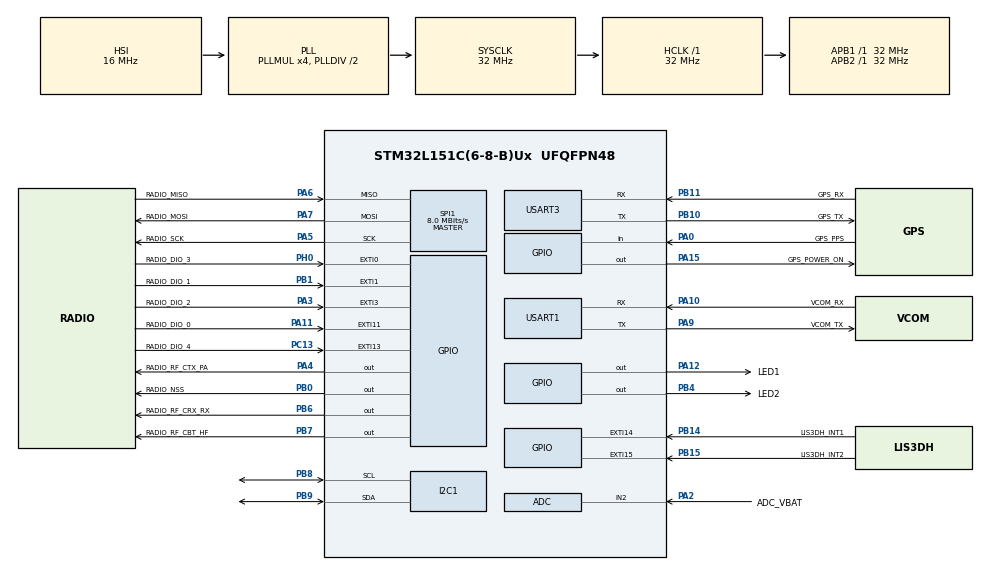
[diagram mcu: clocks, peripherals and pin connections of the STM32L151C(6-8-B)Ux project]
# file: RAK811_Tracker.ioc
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ADC.Channel-0\#ChannelRegularConversion=ADC_CHANNEL_2
ADC.ClockPrescaler=ADC_CLOCK_ASYNC_DIV1
ADC.ContinuousConvMode=DISABLE
ADC.DMAContinuousRequests=DISABLE
ADC.DataAlign=ADC_DATAALIGN_RIGHT
ADC.DiscontinuousConvMode=DISABLE
ADC.EOCSelection=ADC_EOC_SEQ_CONV
ADC.EnableAnalogWatchDog=false
ADC.ExternalTrigConv=ADC_SOFTWARE_START
ADC.ExternalTrigConvEdge=ADC_EXTERNALTRIGCONVEDGE_NONE
ADC.InjNumberOfConversion=0
ADC.LowPowerAutoPowerOff=ADC_AUTOPOWEROFF_DISABLE
ADC.LowPowerAutoWait=ADC_AUTOWAIT_DISABLE
ADC.NbrOfConversion=1
ADC.NbrOfConversionFlag=1
ADC.Rank-0\#ChannelRegularConversion=1
ADC.Resolution=ADC_RESOLUTION_12B
ADC.SamplingTime-0\#ChannelRegularConversion=ADC_SAMPLETIME_4CYCLES
ADC.ScanConvMode=ADC_SCAN_DISABLE
Dma.Request0=USART1_TX
Dma.USART1_TX.0.Direction=DMA_MEMORY_TO_PERIPH
Dma.USART1_TX.0.Instance=DMA1_Channel4
Dma.USART1_TX.0.MemDataAlignment=DMA_MDATAALIGN_BYTE
Dma.USART1_TX.0.MemInc=DMA_MINC_ENABLE
Dma.USART1_TX.0.Mode=DMA_NORMAL
Dma.USART1_TX.0.PeriphDataAlignment=DMA_PDATAALIGN_BYTE
Dma.USART1_TX.0.PeriphInc=DMA_PINC_DISABLE
Dma.USART1_TX.0.Priority=DMA_PRIORITY_MEDIUM
FREERTOS.Tasks01=defaultTask,0,128,StartDefaultTask,Default,NULL
I2C1.I2C_Mode=I2C_Fast
Mcu.Family=STM32L1
Mcu.Name=STM32L151C(6-8-B)Ux
Mcu.Package=UFQFPN48
NVIC.ADC1_IRQn=true\:5\:0\:false\:false\:true\:true\:true
NVIC.DMA1_Channel4_IRQn=true\:5\:0\:false\:false\:true\:true\:false
NVIC.EXTI0_IRQn=true\:5\:0\:false\:false\:true\:true\:true
NVIC.EXTI15_10_IRQn=true\:5\:0\:false\:false\:true\:true\:true
NVIC.EXTI1_IRQn=true\:5\:0\:false\:false\:true\:true\:true
NVIC.EXTI3_IRQn=true\:5\:0\:false\:false\:true\:true\:true
NVIC.I2C1_EV_IRQn=true\:5\:0\:false\:false\:true\:true\:true
NVIC.PriorityGroup=NVIC_PRIORITYGROUP_4
NVIC.USART1_IRQn=true\:5\:0\:false\:false\:true\:true\:true
NVIC.USART3_IRQn=true\:5\:0\:false\:false\:true\:true\:true
PA0-WKUP1.GPIO_Label=GPS_PPS
PA0-WKUP1.Signal=GPIO_Input
PA10.GPIO_Label=VCOM_RX
PA10.Mode=Asynchronous
PA10.Signal=USART1_RX
PA11.GPIO_Label=RADIO_DIO_0
PA11.Signal=GPXTI11
PA12.GPIO_Label=LED1
PA12.Signal=GPIO_Output
PA13.Mode=Serial_Wire
PA13.Signal=SYS_JTMS-SWDIO
PA14.Mode=Serial_Wire
PA14.Signal=SYS_JTCK-SWCLK
PA15.GPIO_Label=GPS_POWER_ON
PA15.Signal=GPIO_Output
PA2.GPIO_Label=ADC_VBAT
PA2.Mode=IN2
PA2.Signal=ADC_IN2
PA3.GPIO_Label=RADIO_DIO_2
PA3.Signal=GPXTI3
PA4.GPIO_Label=RADIO_RF_CTX_PA
PA4.Signal=GPIO_Output
PA5.GPIO_Label=RADIO_SCK
PA5.Mode=Full_Duplex_Master
PA5.Signal=SPI1_SCK
PA6.GPIO_Label=RADIO_MISO
PA6.Mode=Full_Duplex_Master
PA6.Signal=SPI1_MISO
PA7.GPIO_Label=RADIO_MOSI
PA7.Mode=Full_Duplex_Master
PA7.Signal=SPI1_MOSI
PA9.GPIO_Label=VCOM_TX
PA9.Mode=Asynchronous
PA9.Signal=USART1_TX
PB0.GPIO_Label=RADIO_NSS
PB0.GPIO_PuPd=GPIO_PULLUP
PB0.PinState=GPIO_PIN_SET
PB0.Signal=GPIO_Output
PB1.GPIO_Label=RADIO_DIO_1
PB1.Signal=GPXTI1
PB10.GPIO_Label=GPS_TX
PB10.Mode=Asynchronous
PB10.Signal=USART3_TX
PB11.GPIO_Label=GPS_RX
PB11.Mode=Asynchronous
PB11.Signal=USART3_RX
PB14.GPIO_Label=LIS3DH_INT1
PB14.Signal=GPXTI14
PB15.GPIO_Label=LIS3DH_INT2
PB15.Signal=GPXTI15
PB4.GPIO_Label=LED2
PB4.Signal=GPIO_Output
PB6.GPIO_Label=RADIO_RF_CRX_RX
PB6.Signal=GPIO_Output
PB7.GPIO_Label=RADIO_RF_CBT_HF
PB7.Signal=GPIO_Output
PB8.Mode=I2C
PB8.Signal=I2C1_SCL
PB9.Mode=I2C
PB9.Signal=I2C1_SDA
PC13-WKUP2.GPIO_Label=RADIO_DIO_4
PC13-WKUP2.Signal=GPXTI13
PC14-OSC32_IN.Mode=LSE-External-Oscillator
PC14-OSC32_IN.Signal=RCC_OSC32_IN
PC15-OSC32_OUT.Mode=LSE-External-Oscillator
PC15-OSC32_OUT.Signal=RCC_OSC32_OUT
PH0-OSC_IN.GPIO_Label=RADIO_DIO_3
PH0-OSC_IN.Signal=GPXTI0
PH1-OSC_OUT.Signal=RCC_OSC_OUT
ProjectManager.HeapSize=0x200
ProjectManager.StackSize=0x400
ProjectManager.TargetToolchain=TrueSTUDIO
RCC.48MHZClocksFreq_Value=32000000
RCC.AHBFreq_Value=32000000
RCC.APB1Freq_Value=32000000
RCC.APB1TimFreq_Value=32000000
RCC.APB2Freq_Value=32000000
RCC.APB2TimFreq_Value=32000000
RCC.HCLKFreq_Value=32000000
RCC.HSE_VALUE=24000000
RCC.HSI_VALUE=16000000
RCC.MSI_VALUE=2097000
RCC.PLLMUL=RCC_PLL_MUL4
RCC.SYSCLKFreq_VALUE=32000000
RCC.SYSCLKSource=RCC_SYSCLKSOURCE_PLLCLK
RCC.VCOOutputFreq_Value=64000000
SPI1.BaudRatePrescaler=SPI_BAUDRATEPRESCALER_4
SPI1.CalculateBaudRate=8.0 MBits/s
SPI1.Direction=SPI_DIRECTION_2LINES
SPI1.Mode=SPI_MODE_MASTER
SPI1.VirtualType=VM_MASTER
USART1.VirtualMode=VM_ASYNC
USART3.VirtualMode=VM_ASYNC
VP_ADC_TempSens_Input.Mode=IN-TempSens
VP_CRC_VS_CRC.Mode=CRC_Activate
VP_FREERTOS_VS_ENABLE.Mode=Enabled
VP_IWDG_VS_IWDG.Mode=IWDG_Activate
VP_RTC_VS_RTC_Activate.Mode=RTC_Enabled
VP_RTC_VS_RTC_Calendar.Mode=RTC_Calendar
VP_TIM2_VS_ClockSourceINT.Mode=Internal
board=RAK811_Tracker

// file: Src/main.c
/**
  ******************************************************************************
  * @file           : main.c
  * @brief          : Main program body
  ******************************************************************************
  * This notice applies to any and all portions of this file
  * that are not between comment pairs USER CODE BEGIN and
  * USER CODE END. Other portions of this file, whether
  * inserted by the user or by software development tools
  * are owned by their respective copyright owners.
  *
  * Copyright (c) 2018 STMicroelectronics International N.V.
  * All rights reserved.
  *
  * Redistribution and use in source and binary forms, with or without
  * modification, are permitted, provided that the following conditions are met:
  *
  * 1. Redistribution of source code must retain the above copyright notice,
  *    this list of conditions and the following disclaimer.
  * 2. Redistributions in binary form must reproduce the above copyright notice,
  *    this list of conditions and the following disclaimer in the documentation
  *    and/or other materials provided with the distribution.
  * 3. Neither the name of STMicroelectronics nor the names of other
  *    contributors to this software may be used to endorse or promote products
  *    derived from this software without specific written permission.
  * 4. This software, including modifications and/or derivative works of this
  *    software, must execute solely and exclusively on microcontroller or
  *    microprocessor devices manufactured by or for STMicroelectronics.
  * 5. Redistribution and use of this software other than as permitted under
  *    this license is void and will automatically terminate your rights under
  *    this license.
  *
  * THIS SOFTWARE IS PROVIDED BY STMICROELECTRONICS AND CONTRIBUTORS "AS IS"
  * AND ANY EXPRESS, IMPLIED OR STATUTORY WARRANTIES, INCLUDING, BUT NOT
  * LIMITED TO, THE IMPLIED WARRANTIES OF MERCHANTABILITY, FITNESS FOR A
  * PARTICULAR PURPOSE AND NON-INFRINGEMENT OF THIRD PARTY INTELLECTUAL PROPERTY
  * RIGHTS ARE DISCLAIMED TO THE FULLEST EXTENT PERMITTED BY LAW. IN NO EVENT
  * SHALL STMICROELECTRONICS OR CONTRIBUTORS BE LIABLE FOR ANY DIRECT, INDIRECT,
  * INCIDENTAL, SPECIAL, EXEMPLARY, OR CONSEQUENTIAL DAMAGES (INCLUDING, BUT NOT
  * LIMITED TO, PROCUREMENT OF SUBSTITUTE GOODS OR SERVICES; LOSS OF USE, DATA,
  * OR PROFITS; OR BUSINESS INTERRUPTION) HOWEVER CAUSED AND ON ANY THEORY OF
  * LIABILITY, WHETHER IN CONTRACT, STRICT LIABILITY, OR TORT (INCLUDING
  * NEGLIGENCE OR OTHERWISE) ARISING IN ANY WAY OUT OF THE USE OF THIS SOFTWARE,
  * EVEN IF ADVISED OF THE POSSIBILITY OF SUCH DAMAGE.
  *
  ******************************************************************************
  */
#include "main.h"
#include "stm32l1xx_hal.h"
#include "cmsis_os.h"

/* USER CODE BEGIN Includes */
#include "hw.h"
#include "low_power_manager.h"
#include "lora.h"
#include "bsp.h"
#include "timeServer.h"
#include "vcom.h"
#include "version.h"
/* USER CODE END Includes */

ADC_HandleTypeDef hadc;

CRC_HandleTypeDef hcrc;

I2C_HandleTypeDef hi2c1;

IWDG_HandleTypeDef hiwdg;

RTC_HandleTypeDef hrtc;

SPI_HandleTypeDef hspi1;

TIM_HandleTypeDef htim2;

UART_HandleTypeDef huart1;
UART_HandleTypeDef huart3;
DMA_HandleTypeDef hdma_usart1_tx;

osThreadId defaultTaskHandle;

/* USER CODE BEGIN PV */
/* Private variables ---------------------------------------------------------*/

/* USER CODE END PV */

void SystemClock_Config(void);
static void MX_GPIO_Init(void);
static void MX_DMA_Init(void);
static void MX_USART1_UART_Init(void);
static void MX_USART3_UART_Init(void);
static void MX_I2C1_Init(void);
static void MX_ADC_Init(void);
static void MX_RTC_Init(void);
static void MX_CRC_Init(void);
static void MX_IWDG_Init(void);
static void MX_SPI1_Init(void);
static void MX_TIM2_Init(void);
void StartDefaultTask(void const * argument);

/* USER CODE BEGIN PFP */
/* Private function prototypes -----------------------------------------------*/

/* USER CODE END PFP */

int main(void)
{

  /* MCU Configuration----------------------------------------------------------*/

  /* Reset of all peripherals, Initializes the Flash interface and the Systick. */
  HAL_Init();

  /* Configure the system clock */
  SystemClock_Config();

  /* Initialize all configured peripherals */
  MX_GPIO_Init();
  MX_DMA_Init();
  MX_USART1_UART_Init();
  MX_USART3_UART_Init();
  MX_I2C1_Init();
  MX_ADC_Init();
  MX_RTC_Init();
  MX_CRC_Init();
  MX_IWDG_Init();
  MX_SPI1_Init();
  MX_TIM2_Init();

  /* Create the thread(s) */
  /* definition and creation of defaultTask */
  osThreadDef(defaultTask, StartDefaultTask, osPriorityNormal, 0, 128);
  defaultTaskHandle = osThreadCreate(osThread(defaultTask), NULL);

  /* Start scheduler */
  osKernelStart();

  /* We should never get here as control is now taken by the scheduler */

  /* Infinite loop */
  while (1)
  {

  }

}

void SystemClock_Config(void)
{

  RCC_OscInitTypeDef RCC_OscInitStruct;
  RCC_ClkInitTypeDef RCC_ClkInitStruct;
  RCC_PeriphCLKInitTypeDef PeriphClkInit;

    /**Configure the main internal regulator output voltage
    */
  __HAL_PWR_VOLTAGESCALING_CONFIG(PWR_REGULATOR_VOLTAGE_SCALE1);

    /**Initializes the CPU, AHB and APB busses clocks
    */
  RCC_OscInitStruct.OscillatorType = RCC_OSCILLATORTYPE_HSI|RCC_OSCILLATORTYPE_LSI;
  RCC_OscInitStruct.HSIState = RCC_HSI_ON;
  RCC_OscInitStruct.HSICalibrationValue = 16;
  RCC_OscInitStruct.LSIState = RCC_LSI_ON;
  RCC_OscInitStruct.PLL.PLLState = RCC_PLL_ON;
  RCC_OscInitStruct.PLL.PLLSource = RCC_PLLSOURCE_HSI;
  RCC_OscInitStruct.PLL.PLLMUL = RCC_PLL_MUL4;
  RCC_OscInitStruct.PLL.PLLDIV = RCC_PLL_DIV2;
  if (HAL_RCC_OscConfig(&RCC_OscInitStruct) != HAL_OK)
  {
    _Error_Handler(__FILE__, __LINE__);
  }

    /**Initializes the CPU, AHB and APB busses clocks
    */
  RCC_ClkInitStruct.ClockType = RCC_CLOCKTYPE_HCLK|RCC_CLOCKTYPE_SYSCLK
                              |RCC_CLOCKTYPE_PCLK1|RCC_CLOCKTYPE_PCLK2;
  RCC_ClkInitStruct.SYSCLKSource = RCC_SYSCLKSOURCE_PLLCLK;
  RCC_ClkInitStruct.AHBCLKDivider = RCC_SYSCLK_DIV1;
  RCC_ClkInitStruct.APB1CLKDivider = RCC_HCLK_DIV1;
  RCC_ClkInitStruct.APB2CLKDivider = RCC_HCLK_DIV1;

  if (HAL_RCC_ClockConfig(&RCC_ClkInitStruct, FLASH_LATENCY_1) != HAL_OK)
  {
    _Error_Handler(__FILE__, __LINE__);
  }

  PeriphClkInit.PeriphClockSelection = RCC_PERIPHCLK_RTC;
  PeriphClkInit.RTCClockSelection = RCC_RTCCLKSOURCE_LSI;
  if (HAL_RCCEx_PeriphCLKConfig(&PeriphClkInit) != HAL_OK)
  {
    _Error_Handler(__FILE__, __LINE__);
  }

    /**Configure the Systick interrupt time
    */
  HAL_SYSTICK_Config(HAL_RCC_GetHCLKFreq()/1000);

    /**Configure the Systick
    */
  HAL_SYSTICK_CLKSourceConfig(SYSTICK_CLKSOURCE_HCLK);

  /* SysTick_IRQn interrupt configuration */
  HAL_NVIC_SetPriority(SysTick_IRQn, 15, 0);
}

/* ADC init function */
static void MX_ADC_Init(void)
{

  ADC_ChannelConfTypeDef sConfig;

    /**Configure the global features of the ADC (Clock, Resolution, Data Alignment and number of conversion)
    */
  hadc.Instance = ADC1;
  hadc.Init.ClockPrescaler = ADC_CLOCK_ASYNC_DIV1;
  hadc.Init.Resolution = ADC_RESOLUTION_12B;
  hadc.Init.DataAlign = ADC_DATAALIGN_RIGHT;
  hadc.Init.ScanConvMode = ADC_SCAN_DISABLE;
  hadc.Init.EOCSelection = ADC_EOC_SEQ_CONV;
  hadc.Init.LowPowerAutoWait = ADC_AUTOWAIT_DISABLE;
  hadc.Init.LowPowerAutoPowerOff = ADC_AUTOPOWEROFF_DISABLE;
  hadc.Init.ChannelsBank = ADC_CHANNELS_BANK_A;
  hadc.Init.ContinuousConvMode = DISABLE;
  hadc.Init.NbrOfConversion = 1;
  hadc.Init.DiscontinuousConvMode = DISABLE;
  hadc.Init.ExternalTrigConv = ADC_SOFTWARE_START;
  hadc.Init.ExternalTrigConvEdge = ADC_EXTERNALTRIGCONVEDGE_NONE;
  hadc.Init.DMAContinuousRequests = DISABLE;
  if (HAL_ADC_Init(&hadc) != HAL_OK)
  {
    _Error_Handler(__FILE__, __LINE__);
  }

    /**Configure for the selected ADC regular channel its corresponding rank in the sequencer and its sample time.
    */
  sConfig.Channel = ADC_CHANNEL_2;
  sConfig.Rank = ADC_REGULAR_RANK_1;
  sConfig.SamplingTime = ADC_SAMPLETIME_4CYCLES;
  if (HAL_ADC_ConfigChannel(&hadc, &sConfig) != HAL_OK)
  {
    _Error_Handler(__FILE__, __LINE__);
  }

}

/* CRC init function */
static void MX_CRC_Init(void)
{

  hcrc.Instance = CRC;
  if (HAL_CRC_Init(&hcrc) != HAL_OK)
  {
    _Error_Handler(__FILE__, __LINE__);
  }

}

/* I2C1 init function */
static void MX_I2C1_Init(void)
{

  hi2c1.Instance = I2C1;
  hi2c1.Init.ClockSpeed = 400000;
  hi2c1.Init.DutyCycle = I2C_DUTYCYCLE_2;
  hi2c1.Init.OwnAddress1 = 0;
  hi2c1.Init.AddressingMode = I2C_ADDRESSINGMODE_7BIT;
  hi2c1.Init.DualAddressMode = I2C_DUALADDRESS_DISABLE;
  hi2c1.Init.OwnAddress2 = 0;
  hi2c1.Init.GeneralCallMode = I2C_GENERALCALL_DISABLE;
  hi2c1.Init.NoStretchMode = I2C_NOSTRETCH_DISABLE;
  if (HAL_I2C_Init(&hi2c1) != HAL_OK)
  {
    _Error_Handler(__FILE__, __LINE__);
  }

}

/* IWDG init function */
static void MX_IWDG_Init(void)
{

  hiwdg.Instance = IWDG;
  hiwdg.Init.Prescaler = IWDG_PRESCALER_4;
  hiwdg.Init.Reload = 4095;
  if (HAL_IWDG_Init(&hiwdg) != HAL_OK)
  {
    _Error_Handler(__FILE__, __LINE__);
  }

}

/* RTC init function */
static void MX_RTC_Init(void)
{

  RTC_TimeTypeDef sTime;
  RTC_DateTypeDef sDate;

    /**Initialize RTC Only
    */
  hrtc.Instance = RTC;
if(HAL_RTCEx_BKUPRead(&hrtc, RTC_BKP_DR0) != 0x32F2){
  hrtc.Init.HourFormat = RTC_HOURFORMAT_24;
  hrtc.Init.AsynchPrediv = 127;
  hrtc.Init.SynchPrediv = 255;
  hrtc.Init.OutPut = RTC_OUTPUT_DISABLE;
  hrtc.Init.OutPutPolarity = RTC_OUTPUT_POLARITY_HIGH;
  hrtc.Init.OutPutType = RTC_OUTPUT_TYPE_OPENDRAIN;
  if (HAL_RTC_Init(&hrtc) != HAL_OK)
  {
    _Error_Handler(__FILE__, __LINE__);
  }

    /**Initialize RTC and set the Time and Date
    */
  sTime.Hours = 0x0;
  sTime.Minutes = 0x0;
  sTime.Seconds = 0x0;
  sTime.DayLightSaving = RTC_DAYLIGHTSAVING_NONE;
  sTime.StoreOperation = RTC_STOREOPERATION_RESET;
  if (HAL_RTC_SetTime(&hrtc, &sTime, RTC_FORMAT_BCD) != HAL_OK)
  {
    _Error_Handler(__FILE__, __LINE__);
  }

  sDate.WeekDay = RTC_WEEKDAY_MONDAY;
  sDate.Month = RTC_MONTH_JANUARY;
  sDate.Date = 0x1;
  sDate.Year = 0x0;

  if (HAL_RTC_SetDate(&hrtc, &sDate, RTC_FORMAT_BCD) != HAL_OK)
  {
    _Error_Handler(__FILE__, __LINE__);
  }

    HAL_RTCEx_BKUPWrite(&hrtc,RTC_BKP_DR0,0x32F2);
  }

}

/* SPI1 init function */
static void MX_SPI1_Init(void)
{

  /* SPI1 parameter configuration*/
  hspi1.Instance = SPI1;
  hspi1.Init.Mode = SPI_MODE_MASTER;
  hspi1.Init.Direction = SPI_DIRECTION_2LINES;
  hspi1.Init.DataSize = SPI_DATASIZE_8BIT;
  hspi1.Init.CLKPolarity = SPI_POLARITY_LOW;
  hspi1.Init.CLKPhase = SPI_PHASE_1EDGE;
  hspi1.Init.NSS = SPI_NSS_SOFT;
  hspi1.Init.BaudRatePrescaler = SPI_BAUDRATEPRESCALER_4;
  hspi1.Init.FirstBit = SPI_FIRSTBIT_MSB;
  hspi1.Init.TIMode = SPI_TIMODE_DISABLE;
  hspi1.Init.CRCCalculation = SPI_CRCCALCULATION_DISABLE;
  hspi1.Init.CRCPolynomial = 10;
  if (HAL_SPI_Init(&hspi1) != HAL_OK)
  {
    _Error_Handler(__FILE__, __LINE__);
  }

}

/* TIM2 init function */
static void MX_TIM2_Init(void)
{

  TIM_ClockConfigTypeDef sClockSourceConfig;
  TIM_MasterConfigTypeDef sMasterConfig;

  htim2.Instance = TIM2;
  htim2.Init.Prescaler = 0;
  htim2.Init.CounterMode = TIM_COUNTERMODE_UP;
  htim2.Init.Period = 0;
  htim2.Init.ClockDivision = TIM_CLOCKDIVISION_DIV1;
  if (HAL_TIM_Base_Init(&htim2) != HAL_OK)
  {
    _Error_Handler(__FILE__, __LINE__);
  }

  sClockSourceConfig.ClockSource = TIM_CLOCKSOURCE_INTERNAL;
  if (HAL_TIM_ConfigClockSource(&htim2, &sClockSourceConfig) != HAL_OK)
  {
    _Error_Handler(__FILE__, __LINE__);
  }

  sMasterConfig.MasterOutputTrigger = TIM_TRGO_RESET;
  sMasterConfig.MasterSlaveMode = TIM_MASTERSLAVEMODE_DISABLE;
  if (HAL_TIMEx_MasterConfigSynchronization(&htim2, &sMasterConfig) != HAL_OK)
  {
    _Error_Handler(__FILE__, __LINE__);
  }

}

/* USART1 init function */
static void MX_USART1_UART_Init(void)
{

  huart1.Instance = USART1;
  huart1.Init.BaudRate = 115200;
  huart1.Init.WordLength = UART_WORDLENGTH_8B;
  huart1.Init.StopBits = UART_STOPBITS_1;
  huart1.Init.Parity = UART_PARITY_NONE;
  huart1.Init.Mode = UART_MODE_TX_RX;
  huart1.Init.HwFlowCtl = UART_HWCONTROL_NONE;
  huart1.Init.OverSampling = UART_OVERSAMPLING_16;
  if (HAL_UART_Init(&huart1) != HAL_OK)
  {
    _Error_Handler(__FILE__, __LINE__);
  }

}

/* USART3 init function */
static void MX_USART3_UART_Init(void)
{

  huart3.Instance = USART3;
  huart3.Init.BaudRate = 115200;
  huart3.Init.WordLength = UART_WORDLENGTH_8B;
  huart3.Init.StopBits = UART_STOPBITS_1;
  huart3.Init.Parity = UART_PARITY_NONE;
  huart3.Init.Mode = UART_MODE_TX_RX;
  huart3.Init.HwFlowCtl = UART_HWCONTROL_NONE;
  huart3.Init.OverSampling = UART_OVERSAMPLING_16;
  if (HAL_UART_Init(&huart3) != HAL_OK)
  {
    _Error_Handler(__FILE__, __LINE__);
  }

}

static void MX_DMA_Init(void)
{
  /* DMA controller clock enable */
  __HAL_RCC_DMA1_CLK_ENABLE();

  /* DMA interrupt init */
  /* DMA1_Channel4_IRQn interrupt configuration */
  HAL_NVIC_SetPriority(DMA1_Channel4_IRQn, 5, 0);
  HAL_NVIC_EnableIRQ(DMA1_Channel4_IRQn);

}

/** Configure pins as
        * Analog
        * Input
        * Output
        * EVENT_OUT
        * EXTI
*/
static void MX_GPIO_Init(void)
{

  GPIO_InitTypeDef GPIO_InitStruct;

  /* GPIO Ports Clock Enable */
  __HAL_RCC_GPIOC_CLK_ENABLE();
  __HAL_RCC_GPIOH_CLK_ENABLE();
  __HAL_RCC_GPIOA_CLK_ENABLE();
  __HAL_RCC_GPIOB_CLK_ENABLE();

  /*Configure GPIO pin Output Level */
  HAL_GPIO_WritePin(GPIOA, RADIO_RF_CTX_PA_Pin|LED1_Pin|GPS_POWER_ON_Pin, GPIO_PIN_RESET);

  /*Configure GPIO pin Output Level */
  HAL_GPIO_WritePin(RADIO_NSS_GPIO_Port, RADIO_NSS_Pin, GPIO_PIN_SET);

  /*Configure GPIO pin Output Level */
  HAL_GPIO_WritePin(GPIOB, LED2_Pin|RADIO_RF_CRX_RX_Pin|RADIO_RF_CBT_HF_Pin, GPIO_PIN_RESET);

  /*Configure GPIO pin : RADIO_DIO_4_Pin */
  GPIO_InitStruct.Pin = RADIO_DIO_4_Pin;
  GPIO_InitStruct.Mode = GPIO_MODE_IT_RISING;
  GPIO_InitStruct.Pull = GPIO_NOPULL;
  HAL_GPIO_Init(RADIO_DIO_4_GPIO_Port, &GPIO_InitStruct);

  /*Configure GPIO pin : RADIO_DIO_3_Pin */
  GPIO_InitStruct.Pin = RADIO_DIO_3_Pin;
  GPIO_InitStruct.Mode = GPIO_MODE_IT_RISING;
  GPIO_InitStruct.Pull = GPIO_NOPULL;
  HAL_GPIO_Init(RADIO_DIO_3_GPIO_Port, &GPIO_InitStruct);

  /*Configure GPIO pin : GPS_PPS_Pin */
  GPIO_InitStruct.Pin = GPS_PPS_Pin;
  GPIO_InitStruct.Mode = GPIO_MODE_INPUT;
  GPIO_InitStruct.Pull = GPIO_NOPULL;
  HAL_GPIO_Init(GPS_PPS_GPIO_Port, &GPIO_InitStruct);

  /*Configure GPIO pins : RADIO_DIO_2_Pin RADIO_DIO_0_Pin */
  GPIO_InitStruct.Pin = RADIO_DIO_2_Pin|RADIO_DIO_0_Pin;
  GPIO_InitStruct.Mode = GPIO_MODE_IT_RISING;
  GPIO_InitStruct.Pull = GPIO_NOPULL;
  HAL_GPIO_Init(GPIOA, &GPIO_InitStruct);

  /*Configure GPIO pins : RADIO_RF_CTX_PA_Pin LED1_Pin GPS_POWER_ON_Pin */
  GPIO_InitStruct.Pin = RADIO_RF_CTX_PA_Pin|LED1_Pin|GPS_POWER_ON_Pin;
  GPIO_InitStruct.Mode = GPIO_MODE_OUTPUT_PP;
  GPIO_InitStruct.Pull = GPIO_NOPULL;
  GPIO_InitStruct.Speed = GPIO_SPEED_FREQ_LOW;
  HAL_GPIO_Init(GPIOA, &GPIO_InitStruct);

  /*Configure GPIO pin : RADIO_NSS_Pin */
  GPIO_InitStruct.Pin = RADIO_NSS_Pin;
  GPIO_InitStruct.Mode = GPIO_MODE_OUTPUT_PP;
  GPIO_InitStruct.Pull = GPIO_PULLUP;
  GPIO_InitStruct.Speed = GPIO_SPEED_FREQ_LOW;
  HAL_GPIO_Init(RADIO_NSS_GPIO_Port, &GPIO_InitStruct);

  /*Configure GPIO pins : RADIO_DIO_1_Pin LIS3DH_INT1_Pin LIS3DH_INT2_Pin */
  GPIO_InitStruct.Pin = RADIO_DIO_1_Pin|LIS3DH_INT1_Pin|LIS3DH_INT2_Pin;
  GPIO_InitStruct.Mode = GPIO_MODE_IT_RISING;
  GPIO_InitStruct.Pull = GPIO_NOPULL;
  HAL_GPIO_Init(GPIOB, &GPIO_InitStruct);

  /*Configure GPIO pins : LED2_Pin RADIO_RF_CRX_RX_Pin RADIO_RF_CBT_HF_Pin */
  GPIO_InitStruct.Pin = LED2_Pin|RADIO_RF_CRX_RX_Pin|RADIO_RF_CBT_HF_Pin;
  GPIO_InitStruct.Mode = GPIO_MODE_OUTPUT_PP;
  GPIO_InitStruct.Pull = GPIO_NOPULL;
  GPIO_InitStruct.Speed = GPIO_SPEED_FREQ_LOW;
  HAL_GPIO_Init(GPIOB, &GPIO_InitStruct);

  /* EXTI interrupt init*/
  HAL_NVIC_SetPriority(EXTI0_IRQn, 5, 0);
  HAL_NVIC_EnableIRQ(EXTI0_IRQn);

  HAL_NVIC_SetPriority(EXTI1_IRQn, 5, 0);
  HAL_NVIC_EnableIRQ(EXTI1_IRQn);

  HAL_NVIC_SetPriority(EXTI3_IRQn, 5, 0);
  HAL_NVIC_EnableIRQ(EXTI3_IRQn);

  HAL_NVIC_SetPriority(EXTI15_10_IRQn, 5, 0);
  HAL_NVIC_EnableIRQ(EXTI15_10_IRQn);

}

/* StartDefaultTask function */
void StartDefaultTask(void const * argument)
{

  for(;;)
  {
    osDelay(1);
  }
}

void _Error_Handler(char *file, int line)
{
  while(1)
  {
  }
}

/************************ (C) COPYRIGHT STMicroelectronics *****END OF FILE****/
